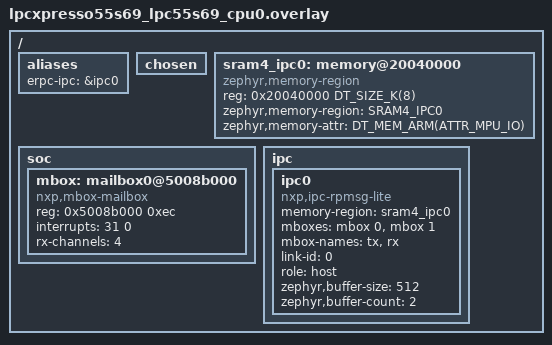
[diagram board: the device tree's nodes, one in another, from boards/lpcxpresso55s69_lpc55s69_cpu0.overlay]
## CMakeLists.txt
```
#
# Copyright 2023-2026 NXP
#
# SPDX-License-Identifier: BSD-3-Clause
#

cmake_minimum_required(VERSION 3.20.0)

set(REMOTE_ZEPHYR_DIR ${CMAKE_CURRENT_BINARY_DIR}/../remote/zephyr)

find_package(Zephyr REQUIRED HINTS $ENV{ZEPHYR_BASE})
project(matrix_multiply_ipc_service)

if(CONFIG_INCLUDE_REMOTE_DIR)
  target_include_directories(zephyr_interface
    INTERFACE ${REMOTE_ZEPHYR_DIR}/include/public)
endif()

enable_language(C CXX)

target_include_directories(app PRIVATE
    ${PROJECT_SOURCE_DIR}/
    ${PROJECT_SOURCE_DIR}/src
    ${PROJECT_SOURCE_DIR}/src/service
)

target_sources(app PRIVATE
    ${PROJECT_SOURCE_DIR}/src/main.cpp
    ${PROJECT_SOURCE_DIR}/src/erpc_error_handler.cpp

    # Generated shim code
    ${PROJECT_SOURCE_DIR}/src/service/c_erpc_matrix_multiply_client.cpp
    ${PROJECT_SOURCE_DIR}/src/service/erpc_matrix_multiply_client.cpp
    ${PROJECT_SOURCE_DIR}/src/service/erpc_matrix_multiply_interface.cpp
)

if (CONFIG_BOARD_MIMXRT685_EVK OR CONFIG_BOARD_MIMXRT700_EVK)
    include("${ZEPHYR_BASE}/samples/boards/nxp/adsp/rtxxx/common/dsp-load.cmake")
endif()
```

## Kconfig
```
#
# Copyright 2023-2026 NXP
#
# SPDX-License-Identifier: BSD-3-Clause
#

source "Kconfig.zephyr"

config INCLUDE_REMOTE_DIR
	bool "Include remote core header directory"
	help
	  Include remote build header files. Can be used if primary image
	  needs to be aware of size or base address of secondary image
```

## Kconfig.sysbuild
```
#
# Copyright 2023-2026 NXP
#
# SPDX-License-Identifier: BSD-3-Clause
#

source "share/sysbuild/Kconfig"

config RPMSG_LITE_REMOTE_BOARD
string
	default "lpcxpresso55s69/lpc55s69/cpu1" if $(BOARD) = "lpcxpresso55s69"
	default "mimxrt1170_evk/mimxrt1176/cm4" if $(BOARD) = "mimxrt1170_evk"
	default "mimxrt1160_evk/mimxrt1166/cm4" if $(BOARD) = "mimxrt1160_evk"
	default "mimxrt1170_evkb/mimxrt1176/cm4" if $(BOARD) = "mimxrt1170_evkb"
	default "mimxrt700_evk/mimxrt798s/cm33_cpu1" if $(BOARD) = "mimxrt700_evk"
```

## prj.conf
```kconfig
#
# Copyright 2026 NXP
#
# SPDX-License-Identifier: BSD-3-Clause
#

CONFIG_PRINTK=y

# Compiler
CONFIG_MAIN_STACK_SIZE=4096
CONFIG_HEAP_MEM_POOL_SIZE=8192

# eRPC
CONFIG_ERPC=y
CONFIG_ERPC_TRANSPORT_IPC_SERVICE=y

# RPMSG Lite
CONFIG_RL_API_HAS_ZEROCOPY=y
CONFIG_RL_USE_STATIC_API=y
CONFIG_TIMESLICE_SIZE=1

# CONFIG_INIT_STACKS=y
# CONFIG_NO_OPTIMIZATIONS=y
# CONFIG_DEBUG_THREAD_INFO=y
# CONFIG_THREAD_STACK_INFO=y
```

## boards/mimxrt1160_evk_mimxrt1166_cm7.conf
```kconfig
#
# Copyright 2026 NXP
#
# SPDX-License-Identifier: Apache-2.0
#

CONFIG_MBOX_NXP_IMX_MU=y
CONFIG_SECOND_CORE_MCUX=y
CONFIG_INCLUDE_REMOTE_DIR=y
```

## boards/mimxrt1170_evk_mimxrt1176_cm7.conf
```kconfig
#
# Copyright 2026 NXP
#
# SPDX-License-Identifier: Apache-2.0
#

CONFIG_INCLUDE_REMOTE_DIR=y
CONFIG_SECOND_CORE_MCUX=y
```

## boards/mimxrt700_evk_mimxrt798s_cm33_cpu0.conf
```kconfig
#
# Copyright 2026 NXP
#
# SPDX-License-Identifier: Apache-2.0
#

CONFIG_SECOND_CORE_MCUX=y
CONFIG_INCLUDE_REMOTE_DIR=y
CONFIG_DCACHE=n
```

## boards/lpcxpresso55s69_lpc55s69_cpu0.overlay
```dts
/*
 * Copyright 2026 NXP
 *
 * SPDX-License-Identifier: Apache-2.0
 */

#include <zephyr/dt-bindings/ipc_service/static_vrings.h>
#include <zephyr/dt-bindings/memory-attr/memory-attr-arm.h>

/ {
	aliases {
		erpc-ipc = &ipc0;  /* Select which IPC instance to use for eRPC */
	};

	chosen {
		/* Delete ipc chosen property where old IPM mailbox driver below is
		 * configured.
		 */
		/delete-property/ zephyr,ipc;
		/delete-property/ zephyr,ipc_shm;
	};

	/* Define memory regions for IPC
	 * Note that shared memory must have specific MPU attributes set.
	 */
	sram4_ipc0: memory@20040000 {
		compatible = "zephyr,memory-region", "mmio-sram";
		reg = <0x20040000 DT_SIZE_K(8)>;
		zephyr,memory-region = "SRAM4_IPC0";
		zephyr,memory-attr = <DT_MEM_ARM(ATTR_MPU_IO)>;
	};

	soc {
		/* Delete IPM Driver node nxp,lpc-mailbox */
		/delete-node/ mailbox@8b000;

		/* Attach MBOX driver to Mailbox Unit */
		mbox: mailbox0@5008b000 {
			compatible = "nxp,mbox-mailbox";
			reg = <0x5008b000 0xec>;
			interrupts = <31 0>;
			rx-channels = <4>;
			#mbox-cells = <1>;
			status = "okay";
		};
	};

	ipc {
		/delete-node/ ipc0;

		ipc0: ipc0 {
			compatible = "nxp,ipc-rpmsg-lite";
			memory-region = <&sram4_ipc0>;
			mboxes = <&mbox 0>, <&mbox 1>;
			mbox-names = "tx", "rx";
			link-id = <0>;
			role = "host";
			zephyr,buffer-size = <512>;
			zephyr,buffer-count = <2>;
			status = "okay";
		};
	};
};
```

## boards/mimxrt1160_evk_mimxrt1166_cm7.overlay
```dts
/*
 * Copyright 2026 NXP
 *
 * SPDX-License-Identifier: Apache-2.0
 */

#include <zephyr/dt-bindings/ipc_service/static_vrings.h>
#include <zephyr/dt-bindings/memory-attr/memory-attr-arm.h>

/ {
	aliases {
		erpc-ipc = &ipc0;  /* Select which IPC instance to use for eRPC */
	};

	chosen {
		/* Delete ipc chosen property where old IPM mailbox driver below is
		 * configured.
		 */
		/delete-property/ zephyr,ipc;
		/delete-property/ zephyr,ipc_shm;

		zephyr,console = &lpuart1;
		zephyr,shell-uart = &lpuart1;
	};

	/* Define memory regions for IPC
	 * Note that shared memory must have specific MPU attributes set.
	 */
	ocram2_ipc0: memory@202c0000 {
		compatible = "zephyr,memory-region", "mmio-sram";
		reg = <0x202c0000 DT_SIZE_K(32)>;
		zephyr,memory-region = "OCRAM2_IPC0";
		zephyr,memory-attr = <DT_MEM_ARM(ATTR_MPU_IO)>;
	};

	soc {
		/* Delete IPM Driver node nxp,imx-mu */
		/delete-node/ mailbox@40c48000;

		/* Attach MBOX driver to MU Unit */
		mbox: mbox@40c48000 {
			compatible = "nxp,mbox-imx-mu";
			reg = <0x40c48000 0x4000>;
			interrupts = <118 0>;
			rx-channels = <4>;
			#mbox-cells = <1>;
			status = "okay";
		};
	};

	ipc {
		/delete-node/ ipc0;

		ipc0: ipc0 {
			compatible = "nxp,ipc-rpmsg-lite";
			memory-region = <&ocram2_ipc0>;
			mboxes = <&mbox 0>, <&mbox 1>;
			mbox-names = "tx", "rx";
			link-id = <0>;
			role = "host";
			zephyr,buffer-size = <512>;
			zephyr,buffer-count = <2>;
			status = "okay";
		};
	};
};
```

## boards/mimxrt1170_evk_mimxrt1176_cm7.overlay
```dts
/*
 * Copyright 2026 NXP
 *
 * SPDX-License-Identifier: Apache-2.0
 */

#include <zephyr/dt-bindings/ipc_service/static_vrings.h>
#include <zephyr/dt-bindings/memory-attr/memory-attr-arm.h>

/ {
	aliases {
		erpc-ipc = &ipc0;  /* Select which IPC instance to use for eRPC */
	};

	chosen {
		/* Delete ipc chosen property where old IPM mailbox driver bellow is
		 * configured.
		 */
		/delete-property/ zephyr,ipc;
		/delete-property/ zephyr,ipc_shm;

		zephyr,console = &lpuart1;
		zephyr,shell-uart = &lpuart1;
	};

	/* Define memory regions for IPC
	 * Note that shared memory must have specific MPU attributes set.
	 */
	ocram2_ipc0: memory@202c0000{
		compatible = "zephyr,memory-region", "mmio-sram";
		reg = <0x202c0000 DT_SIZE_K(32)>;
		zephyr,memory-region="OCRAM2_IPC0";
		zephyr,memory-attr = <( DT_MEM_ARM(ATTR_MPU_IO))>;
	};

	soc {
		/* Delete IPM Driver node nxp,imx-mu */
		/delete-node/ mailbox@40c48000;

		/* Attach MBOX driver to MU Unit */
		mbox:mbox@40c48000 {
			compatible = "nxp,mbox-imx-mu";
			reg = <0x40c48000 0x4000>;
			interrupts = <118 0>;
			rx-channels = <4>;
			#mbox-cells = <1>;
			status = "okay";
		};
	};

	ipc {
		/delete-node/ ipc0;

		ipc0: ipc0 {
			compatible = "nxp,ipc-rpmsg-lite";
			memory-region = <&ocram2_ipc0>;
			/* With ipc-rpmsg-lite we can reuse same MBOX channel per IPC instance */
			mboxes = <&mbox 2>, <&mbox 3>;
			mbox-names = "tx", "rx";
			link-id = <0>;
			role = "host";
			zephyr,buffer-size = <512>;
			zephyr,buffer-count = <2>;
			status = "okay";
		};
	};
};
```

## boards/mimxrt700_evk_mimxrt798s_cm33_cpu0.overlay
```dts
/*
 * Copyright 2026 NXP
 *
 * SPDX-License-Identifier: Apache-2.0
 */

#include <zephyr/dt-bindings/ipc_service/static_vrings.h>
#include <zephyr/dt-bindings/memory-attr/memory-attr-arm.h>

/ {
	aliases {
		erpc-ipc = &ipc0;  /* Select which IPC instance to use for eRPC */
	};

	/* Define memory regions for IPC */
	sram1_ipc0: memory@20200000 {
		compatible = "zephyr,memory-region", "mmio-sram";
		reg = <0x20200000 DT_SIZE_K(16)>;
		zephyr,memory-region = "SRAM1_IPC0";
		zephyr,memory-attr = <DT_MEM_ARM(ATTR_MPU_IO)>;
	};

	ipc {
		/delete-node/ ipc0;

		ipc0: ipc0 {
			compatible = "nxp,ipc-rpmsg-lite";
			memory-region = <&sram1_ipc0>;
			mboxes = <&mbox1_a 0>, <&mbox1_a 1>;
			mbox-names = "tx", "rx";
			link-id = <0>;
			role = "host";
			zephyr,buffer-size = <512>;
			zephyr,buffer-count = <2>;
			status = "okay";
		};
	};
};
```

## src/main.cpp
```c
/*
 * Copyright 2023-2026 NXP
 *
 * SPDX-License-Identifier: BSD-3-Clause
 */

#include <zephyr/kernel.h>

#include "erpc_client_setup.h"
#include "erpc_transport_setup.h"
#include "erpc_matrix_multiply_common.h"
#include "c_erpc_matrix_multiply_client.h"
#include "erpc_error_handler.h"

#if defined(CONFIG_BOARD_MIMXRT685_EVK) || defined(CONFIG_BOARD_MIMXRT700_EVK)
#include "dsp.h"
#endif

/*******************************************************************************
 * Definitions
 ******************************************************************************/
#define MASTER_INIT_DELAY_MS (500U)

#define MATRIX_ITEM_MAX_VALUE (50)

/*******************************************************************************
 * Variables
 ******************************************************************************/
extern bool g_erpc_error_occurred;

/*******************************************************************************
 * Prototypes
 ******************************************************************************/

/*******************************************************************************
 * Code
 ******************************************************************************/

/*!
 * @brief Fill matrices by random values
 */
static void fill_matrices(Matrix matrix1_ptr, Matrix matrix2_ptr)
{
    int32_t a, b;

    /* Fill both matrices by random values */
    for (a = 0; a < matrix_size; ++a)
    {
        for (b = 0; b < matrix_size; ++b)
        {
            matrix1_ptr[a][b] = rand() % MATRIX_ITEM_MAX_VALUE;
            matrix2_ptr[a][b] = rand() % MATRIX_ITEM_MAX_VALUE;
        }
    }
}

/*!
 * @brief Printing a matrix to the console
 */
static void print_matrix(Matrix matrix_ptr)
{
    int32_t a, b;

    for (a = 0; a < matrix_size; ++a)
    {
        for (b = 0; b < matrix_size; ++b)
        {
            printk("%4i ", matrix_ptr[a][b]);
        }
        printk("\r\n");
    }
}

int main(void)
{
    Matrix matrix1 = { 0 }, matrix2 = { 0 }, result_matrix = { 0 };

    printk("\r\n");
    printk("*************************************************\r\n");
    printk("* eRPC Matrix Multiply Demo - Master/Host Core *\r\n");
    printk("*************************************************\r\n");
    printk("\r\n");

#if defined(CONFIG_BOARD_MIMXRT685_EVK) || defined(CONFIG_BOARD_MIMXRT700_EVK)
    /* Start DSP core */
    printk("Starting DSP core...\r\n");
    dsp_start();
    k_sleep(K_MSEC(500));
#endif

    /* Zephyr IPC Service transport layer initialization */
    printk("Initializing Zephyr IPC Service transport...\r\n");
    erpc_transport_t transport = erpc_transport_zephyr_ipc_master_init(CONFIG_ERPC_ENDPOINT_NAME, MASTER_INIT_DELAY_MS);

    if (transport == NULL)
    {
        printk("ERROR: Failed to initialize eRPC transport\r\n");
        return -1;
    }

    printk("Transport initialized successfully\r\n");

    /* MessageBufferFactory initialization */
    erpc_mbf_t message_buffer_factory;
    message_buffer_factory = erpc_mbf_ipc_service_init(transport);

    /* eRPC client side initialization */
    erpc_client_t client = erpc_client_init(transport, message_buffer_factory);
    initMatrixMultiplyService_client(client);

    /* Set default error handler */
    erpc_client_set_error_handler(client, erpc_error_handler);

    printk("eRPC client initialized\r\n");
    printk("\r\n");

    /* Fill both matrices by random values */
    fill_matrices(matrix1, matrix2);

    /* Print both matrices on the console */
    printk("Matrix #1\r\n");
    printk("=========\r\n");
    print_matrix(matrix1);

    printk("\r\nMatrix #2\r\n");
    printk("=========\r\n");
    print_matrix(matrix2);

    for (;;)
    {
        printk("\r\nSending eRPC request to remote core...\r\n");

        /* Call remote matrix multiply function */
        erpcMatrixMultiply(matrix1, matrix2, result_matrix);

        /* Check if some error occurred in eRPC */
        if (g_erpc_error_occurred)
        {
            printk("ERROR: eRPC error occurred, exiting...\r\n");
            break;
        }

        printk("Received result from remote core\r\n");
        printk("\r\nResult matrix\r\n");
        printk("=============\r\n");
        print_matrix(result_matrix);

        /* Wait before next iteration */
        k_sleep(K_MSEC(1000));

        /* Fill both matrices by random values for next iteration */
        fill_matrices(matrix1, matrix2);

        /* Print both matrices on the console */
        printk("\r\nMatrix #1\r\n");
        printk("=========\r\n");
        print_matrix(matrix1);

        printk("\r\nMatrix #2\r\n");
        printk("=========\r\n");
        print_matrix(matrix2);
    }

    /* Cleanup on error */
    printk("Cleaning up...\r\n");
    erpc_client_deinit(client);
    erpc_mbf_dynamic_deinit(message_buffer_factory);
    erpc_transport_zephyr_ipc_master_deinit(transport);

    for (;;)
    {
        k_sleep(K_FOREVER);
    }

    return 0;
}
```

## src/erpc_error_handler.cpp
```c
/*
 * Copyright (c) 2016, Freescale Semiconductor, Inc.
 * Copyright 2016-2017 NXP
 * All rights reserved.
 *
 * SPDX-License-Identifier: BSD-3-Clause
 */

#include "erpc_error_handler.h"
#include <zephyr/kernel.h>

////////////////////////////////////////////////////////////////////////////////
// Variables
////////////////////////////////////////////////////////////////////////////////

extern bool g_erpc_error_occurred;
bool g_erpc_error_occurred = false;

////////////////////////////////////////////////////////////////////////////////
// Code
////////////////////////////////////////////////////////////////////////////////

void erpc_error_handler(erpc_status_t err, uint32_t functionID)
{
    switch (err)
    {
        case kErpcStatus_Fail:
            printk("\r\nGeneric failure.");
            break;

        case kErpcStatus_InvalidArgument:
            printk("\r\nArgument is an invalid value.");
            break;

        case kErpcStatus_Timeout:
            printk("\r\nOperated timed out.");
            break;

        case kErpcStatus_InvalidMessageVersion:
            printk("\r\nMessage header contains an unknown version.");
            break;

        case kErpcStatus_ExpectedReply:
            printk("\r\nExpected a reply message but got another message type.");
            break;

        case kErpcStatus_CrcCheckFailed:
            printk("\r\nMessage is corrupted.");
            break;

        case kErpcStatus_BufferOverrun:
            printk("\r\nAttempt to read or write past the end of a buffer.");
            break;

        case kErpcStatus_UnknownName:
            printk("\r\nCould not find host with given name.");
            break;

        case kErpcStatus_ConnectionFailure:
            printk("\r\nFailed to connect to host.");
            break;

        case kErpcStatus_ConnectionClosed:
            printk("\r\nConnected closed by peer.");
            break;

        case kErpcStatus_MemoryError:
            printk("\r\nMemory allocation error.");
            break;

        case kErpcStatus_ServerIsDown:
            printk("\r\nServer is stopped.");
            break;

        case kErpcStatus_InitFailed:
            printk("\r\nTransport layer initialization failed.");
            break;

        case kErpcStatus_ReceiveFailed:
            printk("\r\nFailed to receive data.");
            break;

        case kErpcStatus_SendFailed:
            printk("\r\nFailed to send data.");
            break;

        /* no error occurred */
        case kErpcStatus_Success:
            return;

        /* unhandled error */
        default:
            printk("\r\nUnhandled error occurred.");
            break;
    }

    /* When error occurred on client side. */
    if (functionID != 0)
    {
        printk("Function id '%u'.", (unsigned int)functionID);
    }
    printk("\r\n");

    /* error occurred */
    g_erpc_error_occurred = true;
}
```
